# D1H register map
Vendor: Allwinner; File version: 1.0
Registers are 32-bit, read-write, reset 0x0 unless marked. A register's access mark holds for its fields unless they carry their own. Offsets are from the block's base; [hi:lo] are bit positions; {n}, {i} and the like mark numbered series.

## SMHC[{n}] — SD/MMC Host Controller
Base 0x04020000; array of 3, step 0x1000
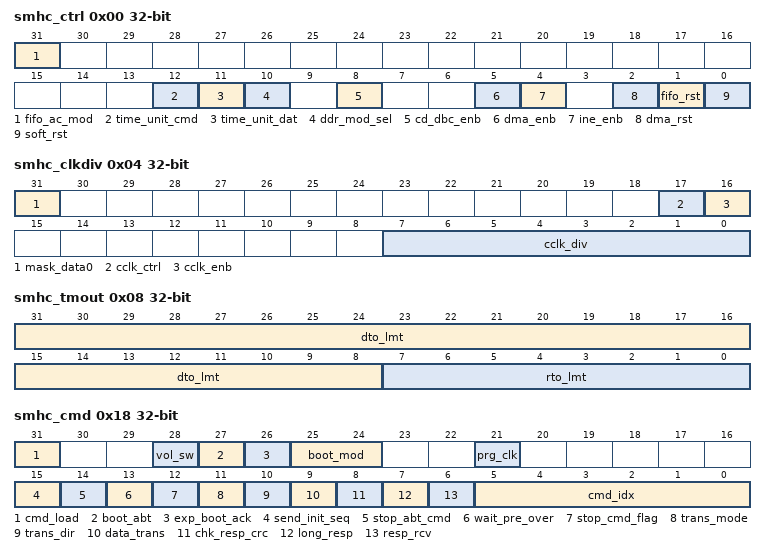
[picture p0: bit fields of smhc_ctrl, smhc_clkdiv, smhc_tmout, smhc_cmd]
0x00 smhc_ctrl — Control Register
  [31] fifo_ac_mod — FIFO Accesss Mode
    0=DMA (DMA bus); 1=AHB (AHB bus)
  [12] time_unit_cmd — Time unit for command line
    0=C1 (1 card clock period); 1=C256 (256 card clock period)
  [11] time_unit_dat — Time unit for data line
    0=C1 (1 card clock period); 1=C256 (256 card clock period)
  [10] ddr_mod_sel — DDR Mode Select
    0=SDR (SDR mode); 1=DDR (DDR mode)
  [8] cd_dbc_enb — Card Detect (Data[3] status) De-bounce Enable
    0=DISABLE (Disable de-bounce); 1=ENABLE (Enable de-bounce)
  [5] dma_enb — DMA Global Enable
    0=DISABLE (Disable DMA to transfer data via AHB bus); 1=ENABLE (Enable DMA to transfer data)
  [4] ine_enb — GLobal Interrupt Enable
    0=DISABLE (Disable interrupts); 1=ENABLE (Enable interrupts)
  [2] dma_rst — DMA Reset
  [1] fifo_rst — FIFO Reset
    0=NO_EFFECT; 1=RESET
  [0] soft_rst — Software Reset
    0=NO_EFFECT; 1=RESET
0x04 smhc_clkdiv — Clock Control Register
  [31] mask_data0
    0=NOT_MASK (Do not mask data0 when update clock); 1=MASK (Mask data0 when update clock)
  [17] cclk_ctrl — Card Clock Output Control
    0=ON (Card clock is always on); 1=OFF_IDLE (Turn off card clock when FSM is in IDLE state)
  [16] cclk_enb — Card Clock Enable
    0=OFF (Card Clock is off); 1=ON (Card Clock is on)
  [7:0] cclk_div — Card Clock Divider
0x08 smhc_tmout — Time Out Register
  [31:8] dto_lmt — Data Iimeout Limit
  [7:0] rto_lmt — Response Timeout Limit
0x0C smhc_ctype — Bus Width Register
  [1:0] card_wid — Card Width
    0=B1 (1-bit width); 1=B4 (4-bit width); 2=B8 (8-bit width)
0x10 smhc_blksiz — Block Size Register
  [15:0] blk_sz — Block SIze
0x14 smhc_bytcnt — Byte Count Register
0x18 smhc_cmd — Command Register
  [31] cmd_load — Start Command
  [28] vol_sw — Voltage Switch
    0=NORMAL (Normal command); 1=VOLTAGE_SWITCH (Voltage switch command, set for CMD11 only)
  [27] boot_abt — Boot Abort
  [26] exp_boot_ack — Expect Boot Acknowledge
  [25:24] boot_mod — Boot Mode
    0=NORMAL (Normal command); 1=MANDATORY_BOOT (Mandatory Boot operation); 2=ALTERNATE_BOOT (Alternate Boot operation)
  [21] prg_clk — Change Clock
    0=NORMAL (Normal command); 1=CHANGE (Change Card Clock)
  [15] send_init_seq — Send Initialization
    0=NORMAL (Normal command sending); 1=INIT_CMD (Send initialization sequence before sending this command)
  [14] stop_abt_cmd — Stop Abort Command
    0=NORMAL (Normal command sending); 1=STOP (Send Stop or Abort command to stop the current data transfer in progress)
  [13] wait_pre_over — Wait for Data Transfer Over
    0=AT_ONCE (Send command at once, does not care about data transferring); 1=WAIT (Wait for data transfer completion before sending the current command)
  [12] stop_cmd_flag — Send Stop CMD Automatically (CMD12)
    0=NO_STOP (Do not send stop command at the end of the data transfer); 1=AUTO_STOP (Send stop command automatically at the end of the data transfer)
  [11] trans_mode — Transfer Mode
    0=BLOCK (Block data transfer command); 1=STREAM (Stream data transfer commmand)
  [10] trans_dir — Transfer Direction
    0=READ (Read operation); 1=WRITE (Write operation)
  [9] data_trans — Data Transfer
    0=WITHOUT (Without data transfer); 1=WITH (With data transfer)
  [8] chk_resp_crc — Check Response CRC
    0=NOT_CHECK (Do not check response CRC); 1=CHECK (Check response CRC)
  [7] long_resp — Response Type
    0=SHORT (Short Response (48 bits)); 1=LONG (Long Response (136 bits))
  [6] resp_rcv — Response Receive
    0=WITHOUT (Command without response); 1=WITH (Command with response)
  [5:0] cmd_idx — CMD Index
0x1C smhc_cmdarg — Command Argument Register
{0x20+4i} smhc_resp{i} ro (i=0..3) — Response {i} Register
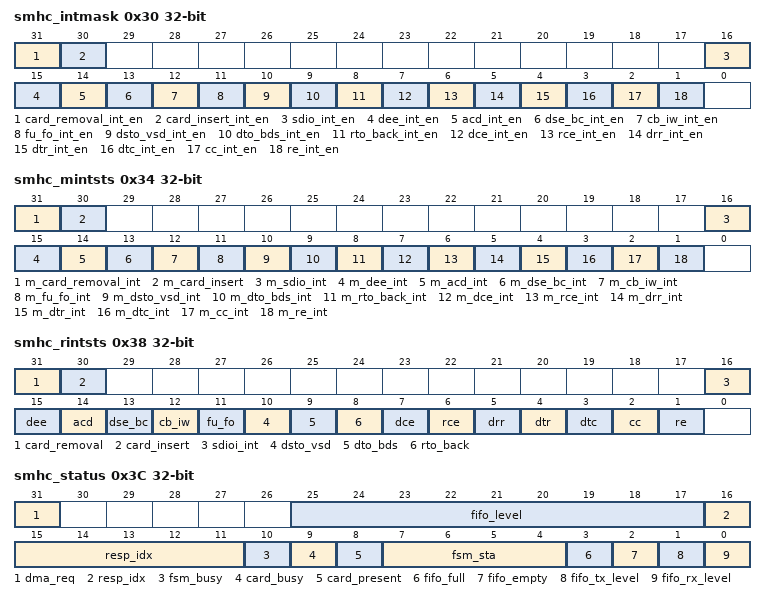
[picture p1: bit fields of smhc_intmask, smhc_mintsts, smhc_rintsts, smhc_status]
0x30 smhc_intmask — Interrupt Mask Register
  [31] card_removal_int_en — Card Removed Interrupt Enable
  [30] card_insert_int_en — Card Inserted Interrupt Enable
  [16] sdio_int_en — SDIO Interrupt Enable
  [15] dee_int_en — Data End-bit Error Interrupt Enable
  [14] acd_int_en — Auto Command Done Interrupt Enable
  [13] dse_bc_int_en — Data Start Error Interrupt Enable
  [12] cb_iw_int_en — Command Busy and Illegal Write Interrupt Enable
  [11] fu_fo_int_en — FIFO Underrun/Overflow Interrupt Enable
  [10] dsto_vsd_int_en — Data Starvation Timeout/V1.8 Switch Done Interrupt Enable
  [9] dto_bds_int_en — Data Timeout/Boot Data Start Interrupt Enable
  [8] rto_back_int_en — Response Timeout/Boot ACK Received Interrupt Enable
  [7] dce_int_en — Data CRC Error Interrupt Enable
  [6] rce_int_en — Response CRC Error Interrupt Enable
  [5] drr_int_en — Data Receive Request Interrupt Enable
  [4] dtr_int_en — Data Transmit Request Interrupt Enable
  [3] dtc_int_en — Data Transfer Complete Interrupt Enable
  [2] cc_int_en — Command Complete Interrupt Enable
  [1] re_int_en — Response Error Interrupt Enable
0x34 smhc_mintsts ro — Masked Interrupt Status Register
  [31] m_card_removal_int — Card Removed
  [30] m_card_insert — Card Inserted
  [16] m_sdio_int — SDIO Interrupt
  [15] m_dee_int — Data End-bit Error
  [14] m_acd_int — Auto Command Done
  [13] m_dse_bc_int — Data Start Error/Busy Clear
  [12] m_cb_iw_int — Command Busy and Illegal Write
  [11] m_fu_fo_int — FIFO Underrun/Overflow
  [10] m_dsto_vsd_int — Data Starvation Timeout/V1.8 Switch Done
  [9] m_dto_bds_int — Data Timeout/Boot Data Start
  [8] m_rto_back_int — Response Timeout/Boot ACK Received
  [7] m_dce_int — Data CRC Error
  [6] m_rce_int — Response CRC Error
  [5] m_drr_int — Data Receive Request
  [4] m_dtr_int — Data Transmit Request
  [3] m_dtc_int — Data Transfer Complete
  [2] m_cc_int — Command Complete
  [1] m_re_int — Response Errors
0x38 smhc_rintsts — Raw Interrupt Status Register
  [31] card_removal — Card Removed
  [30] card_insert — Card Inserted
  [16] sdioi_int — SDIO Interrupt
  [15] dee — Data End-bit Error
  [14] acd — Auto Command Done
  [13] dse_bc — Data Start Error/Busy Clear
  [12] cb_iw — Command Busy and Illegal Write
  [11] fu_fo — FIFO Underrun/Overflow
  [10] dsto_vsd — Data Starvation Timeout/V1.8 Switch Done
  [9] dto_bds — Data Timeout/Boot Data Start
  [8] rto_back — Response Timeout/Boot ACK Received
  [7] dce — Data CRC Error
  [6] rce — Response CRC Error
  [5] drr — Data Receive Request
  [4] dtr — Data Transmit Request
  [3] dtc — Data Transfer Complete
  [2] cc — Command Complete
  [1] re — Response Error
0x3C smhc_status ro — Status Register
  [31] dma_req — DMA Request
  [25:17] fifo_level
  [16:11] resp_idx — Response Index
  [10] fsm_busy — Data FSM Busy
  [9] card_busy — Card Data Busy
    0=NOT_BUSY (Card data is not busy); 1=BUSY (Card data is busy)
  [8] card_present — Data[3] Statuss
    0=NOT_PRESENT (The card is not present); 1=PRESENT (The card is present)
  [7:4] fsm_sta — Command FSM States
    0=IDLE; 1=SIS (Send init sequence); 2=TXCSB (TX CMD start bit); 3=TXCTB (TX CMD TX bit); 4=TXCIA (TX CMD index + argument); 5=TXCC (TX CMD CRC7); 6=TXCEB (TX CMD end bit); 7=RXRSB (RX response start bit); 8=RXRIR (RX response IRQ responses); 9=RXRTB (RX response TX bit); 10=RXRCI (RX response CMD index); 11=RXRD (RX response data); 12=RXRC (RX response CRC7); 13=RXREB (RX response end bit); 14=CPWN (CMD path wait NCC); 15=WAIT (Wait; CMD-to-response turn around)
  [3] fifo_full — sFIFO Full
    0=NOT_FULL (FIFO is not full); 1=FULL (FIFO is full)
  [2] fifo_empty
    0=NOT_SEMPTY (FIFO is not empty); 1=EMPTY (FIFO is empty)
  [1] fifo_tx_level — FIFO TX Water Level Flag
    0=NOT_REACH (FIFO does not reach the transmit trigger level); 1=REACH (FIFO reaches the transmit trigger level)
  [0] fifo_rx_level — FIFO RX Water Level Flag
    0=NOT_REACH (FIFO does not reach the receive trigger level); 1=REACH (FIFO reaches the receive trigger level)
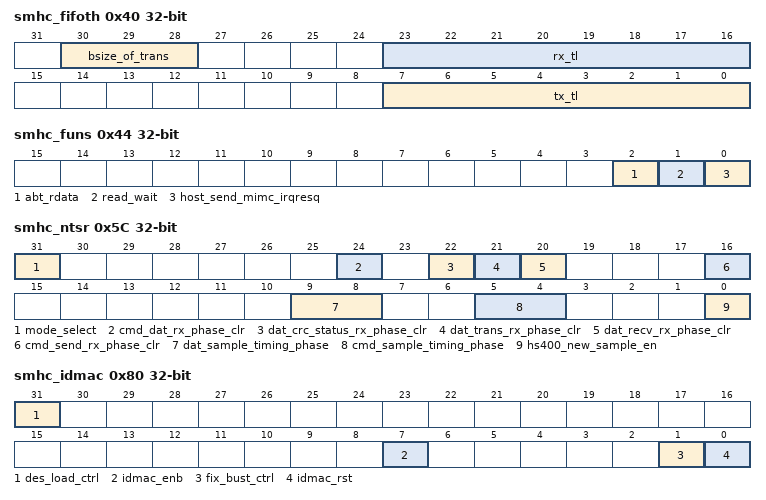
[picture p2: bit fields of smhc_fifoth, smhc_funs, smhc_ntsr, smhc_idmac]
0x40 smhc_fifoth — FIFO Water Level Register
  [30:28] bsize_of_trans — sBurst Size of Multiple Transaction
    0=T1 (1 transfer); 1=T4 (4 transfers); 2=T8 (8 transfers); 3=T16 (16 transfers)
  [23:16] rx_tl — RX Trigger Level
  [7:0] tx_tl — TX Trigger Level
0x44 smhc_funs — FIFO Function Select Register
  [2] abt_rdata — Abort Read Data
    0=IGNORED; 1=ABORT
  [1] read_wait
    0=CLEAR (Clear SDIO read wait); 1=ASSERT (Assert SDIO read wait)
  [0] host_send_mimc_irqresq — Host Send MMC IRQ Response
    0=IGNORED; 1=SEND (Send auto IRQ response)
0x48 smhc_tbc0 ro — Transferred Byte Count between Controller and Card
0x4C smhc_tbc1 ro — Transferred Byte Count between Host Memory and Internal FIFO
0x50 smhc_dbgc — Current Debug Control Register
0x54 smhc_csdc — CRC Status Detect Control Registers
  [3:0] crc_det_para
    6=HS400; 3=OTHER
0x58 smhc_a12a — Auto Command 12 Argument Register
  [15:0] sd_a12a
0x5C smhc_ntsr — SD New Timing Set Register
  [31] mode_select
    0=OLD_MODE (Old mode of Sample/Output Timing); 1=NEW_MODE (New mode of Sample/Output Timing)
  [24] cmd_dat_rx_phase_clr — Clear the input phase of command lines and data lines during the update clock operation
    0=DISABLED; 1=ENABLED
  [22] dat_crc_status_rx_phase_clr — Clear the input phase of data lines before receiving the CRC status
    0=DISABLED; 1=ENABLED
  [21] dat_trans_rx_phase_clr — Clear the input phase of data lines before transferring the data
    0=DISABLED; 1=ENABLED
  [20] dat_recv_rx_phase_clr — Clear the input phase of data lines before receiving the data
    0=DISABLED; 1=ENABLED
  [16] cmd_send_rx_phase_clr — Clear command rx phase before sending the command
    0=DISABLED; 1=ENABLED
  [9:8] dat_sample_timing_phase
    0=O90 (Sample timing phase offset 90); 1=O180 (Sample timing phase offset 180); 2=O270 (Sample timing phase offset 270); 3=O0 (Sample timing phase offset 0 (only for SD2 hs400 mode))
  [5:4] cmd_sample_timing_phase
    0=O90 (Sample timing phase offset 90); 1=O180 (Sample timing phase offset 180); 2=O270 (Sample timing phase offset 270); 3=O0 (Ignore)
  [0] hs400_new_sample_en
    0=DISABLE (Disable hs400 new sample method); 1=ENABLE (Enable hs400 new sample method)
0x78 smhc_hwrst — Hardware Reset Register
  [0] hw_rst
    0=ACTIVE (Active mode); 1=RESET
0x80 smhc_idmac — IDMAC Control Register
  [31] des_load_ctrl wo
  [7] idmac_enb — IDMAC Enable
  [1] fix_bust_ctrl — Fixed Burst
  [0] idmac_rst — DMA Reset
0x84 smhc_dlba — Descriptor List Base Address Register
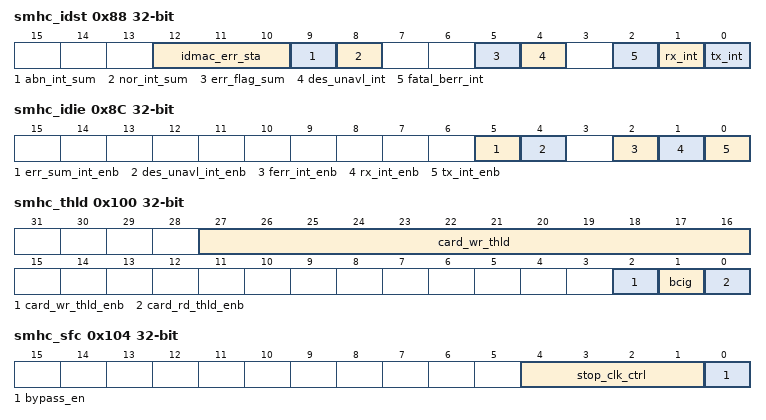
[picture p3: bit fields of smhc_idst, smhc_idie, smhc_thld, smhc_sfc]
0x88 smhc_idst — IDMAC Status Register
  [12:10] idmac_err_sta ro — Error Bits
    1=TRANSMISSION (Host Abort received during the transmission); 2=RECEPTION (Host Abort received during the reception)
  [9] abn_int_sum — Abnormal Interrupt Summary
  [8] nor_int_sum — Normal Interrupt Summary
  [5] err_flag_sum — Card Error Summary
  [4] des_unavl_int — Descriptor Unavailable Interrupt
  [2] fatal_berr_int — Fatal Bus Error Interrupt
  [1] rx_int — Receive Interrupt
  [0] tx_int — Transmit Interrupt
0x8C smhc_idie — IDMAC Interrupt Enable Register
  [5] err_sum_int_enb — Card Error Summary Interrupt Enable
  [4] des_unavl_int_enb — Descriptor Unavailable Interrupt
  [2] ferr_int_enb — Fatal Bus Error Enable
  [1] rx_int_enb — Receive Interrupt Enables
  [0] tx_int_enb — Transmit Interrupt Enable
0x100 smhc_thld — Card Threshold Control Register
  [27:16] card_wr_thld — Card Read/Write Threshold Size
  [2] card_wr_thld_enb — Card Read/Write Threshold Enable
    0=DISABLED (Card write threshold disabled); 1=ENABLED (Card write threshold enabled)
  [1] bcig — Busy Clear Interrupt Generation
    0=DISABLED (Busy clear interrupt disabled); 1=ENABLED (Busy clear interrupt enabled)
  [0] card_rd_thld_enb — Card Read Threshold Enable
    0=DISABLED (Card read threshold disabled); 1=ENABLED (Card read threshold enabled)
0x104 smhc_sfc — Sample FIFO Control Register
  [4:1] stop_clk_ctrl — Stop Clock Control
  [0] bypass_en — Bypass enable
0x108 smhc_a23a — Auto Command 23 Argument Register
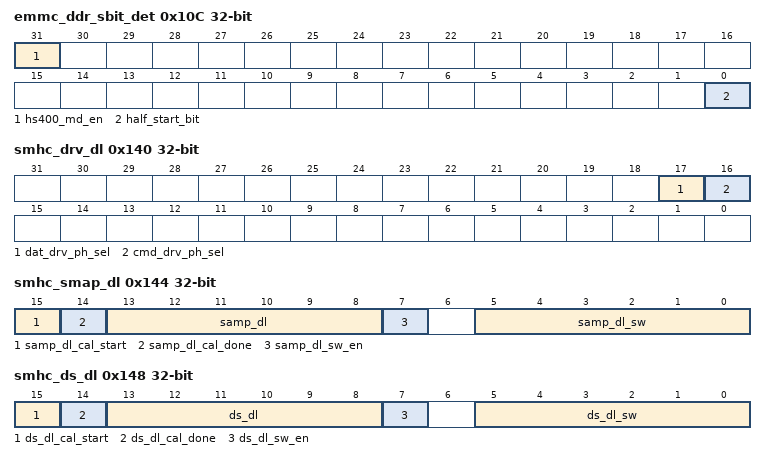
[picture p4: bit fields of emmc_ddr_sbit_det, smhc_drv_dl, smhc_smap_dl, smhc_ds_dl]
0x10C emmc_ddr_sbit_det — eMMC4.5 DDR Start Bit Detection Control Register
  [31] hs400_md_en — HS400 Mode Enable
    0=DISABLED; 1=ENABLED
  [0] half_start_bit — Control for start bit detection mechanism inside mstorage based on duration of start bit
    0=FULL (Full cycle); 1=LESS (Less than one full cycle)
0x138 smhc_ext_cmd — Extended Command Register
  [0] auto_cmd23_en — Send CMD23 Automatically
0x13C smhc_ext_resp ro — Extended Response Register
0x140 smhc_drv_dl — Drive Delay Control Register
  [17] dat_drv_ph_sel — Data Drive Phase Select
  [16] cmd_drv_ph_sel — Command Drive Phase Select
0x144 smhc_smap_dl — Sample Delay Control Register
  [15] samp_dl_cal_start — Sample Delay Calibration Start
  [14] samp_dl_cal_done ro — Sample Delay Calibration Done
  [13:8] samp_dl ro — Sample Delay
  [7] samp_dl_sw_en — Sample Delay Software Enable
  [5:0] samp_dl_sw — Sample Delay Software
0x148 smhc_ds_dl — Data Strobe Delay Control Register
  [15] ds_dl_cal_start — Data Strobe Delay Calibration Start
  [14] ds_dl_cal_done ro — Data Strobe Delay Calibration Done
  [13:8] ds_dl ro — Data Strobe Delay
  [7] ds_dl_sw_en — Sample Delay Software Enable
  [5:0] ds_dl_sw — Data Storbe Delay Software
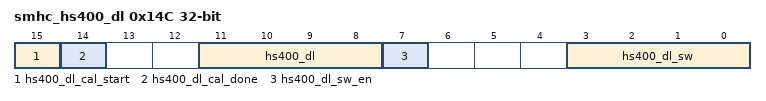
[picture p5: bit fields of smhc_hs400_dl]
0x14C smhc_hs400_dl — HS400 Delay Control Register
  [15] hs400_dl_cal_start — HS400 Delay Calibration Start
  [14] hs400_dl_cal_done ro — HS400 Delay Calibration Done
  [11:8] hs400_dl ro — HS400 Delay
  [7] hs400_dl_sw_en — Sample Delay Software Enable
  [3:0] hs400_dl_sw — HS400 Delay Software
0x200 smhc_fifo — Read/Write FIFO
